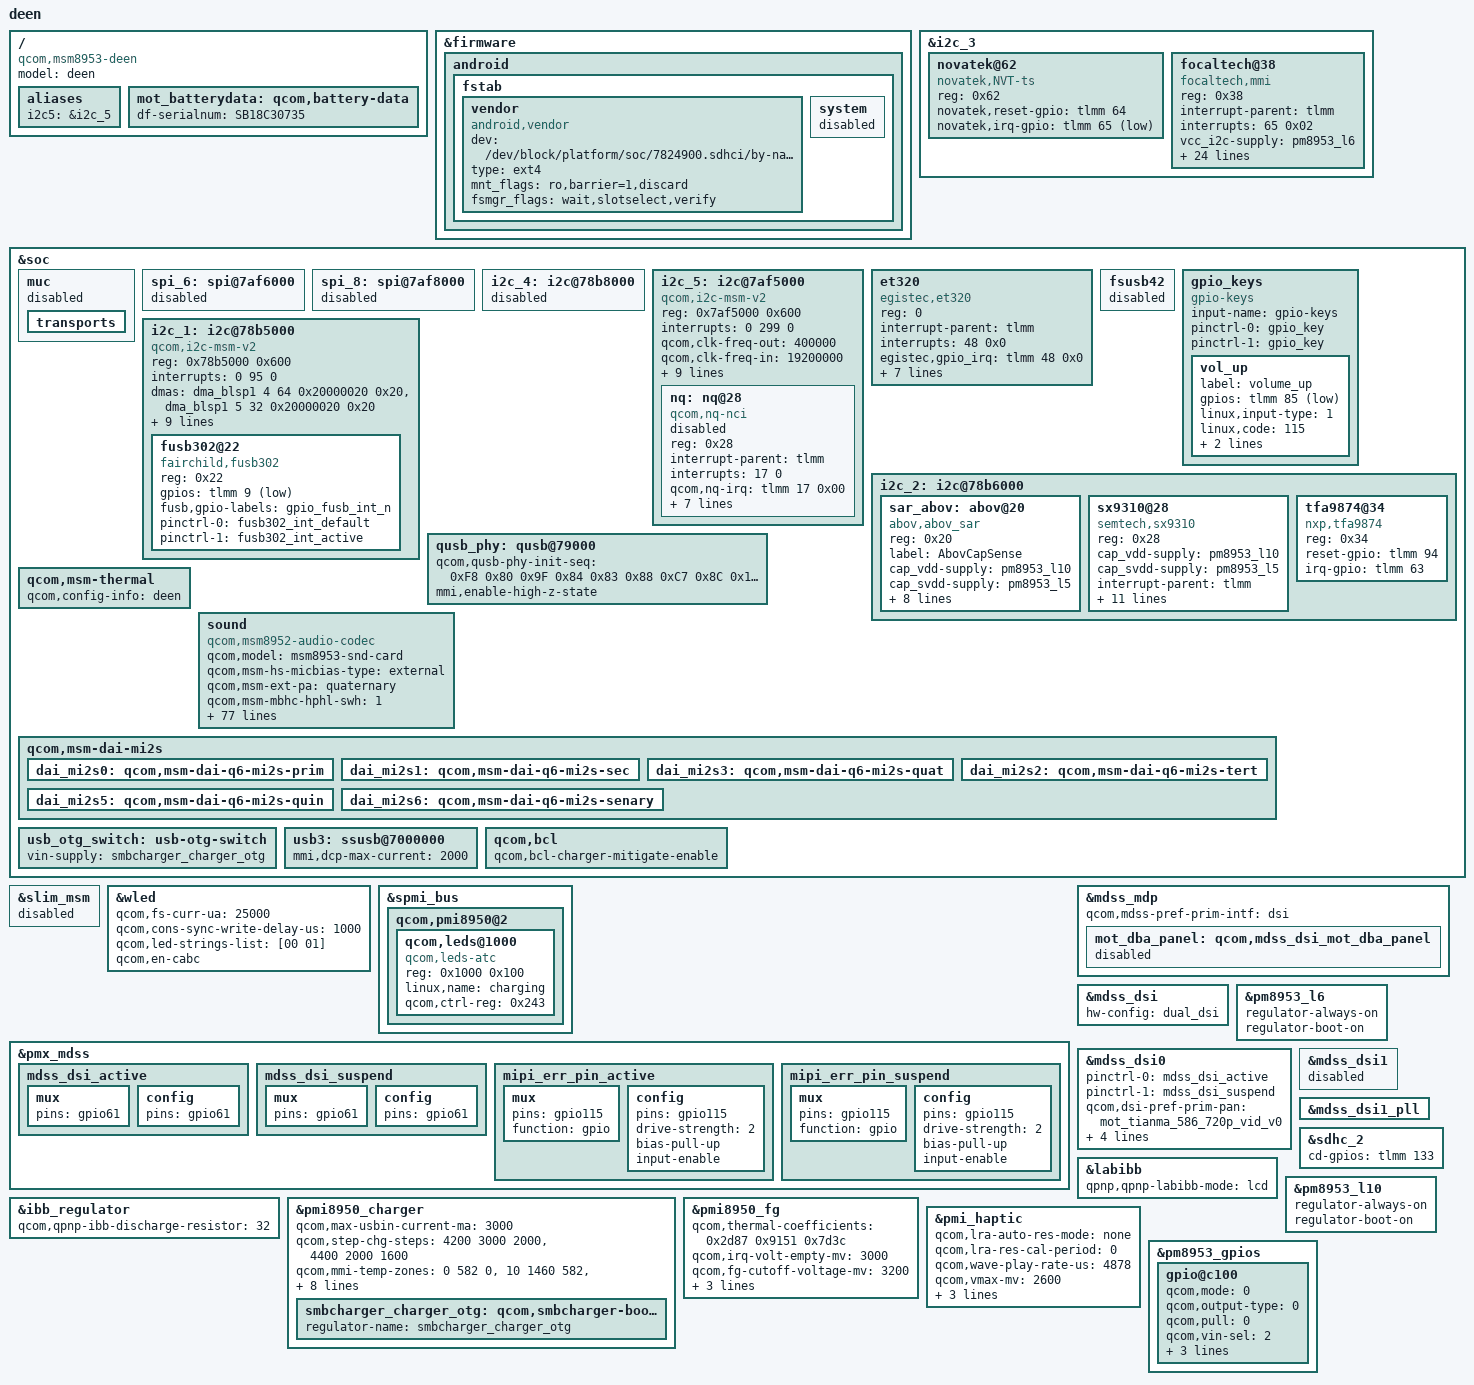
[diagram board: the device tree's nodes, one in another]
/* Copyright (c) 2018, Motorola Mobility Inc. All rights reserved.
 *
 * This program is free software; you can redistribute it and/or modify
 * it under the terms of the GNU General Public License version 2 and
 * only version 2 as published by the Free Software Foundation.
 *
 * This program is distributed in the hope that it will be useful,
 * but WITHOUT ANY WARRANTY; without even the implied warranty of
 * MERCHANTABILITY or FITNESS FOR A PARTICULAR PURPOSE.  See the
 * GNU General Public License for more details.
 */

#include "msm8953-moto-common.dtsi"
#include "dsi-panel-mot-tianma-586-720p-vid.dtsi"
#include "dsi-panel-mot-nova-586-hd-vid.dtsi"
#include "msm8953-deen-pinctrl.dtsi"
#include "msm8953-camera-sensor-mot-deen.dtsi"

 / {
	model = "deen";
	compatible = "qcom,msm8953-deen", "qcom,msm8953-moto",
			"qcom,msm8953";
	aliases {
		i2c5 = &i2c_5;
	};
};

&firmware {
	android {
		fstab {
			vendor {
				compatible = "android,vendor";
				dev = "/dev/block/platform/soc/7824900.sdhci/by-name/vendor";
				type = "ext4";
				mnt_flags = "ro,barrier=1,discard";
				fsmgr_flags = "wait,slotselect,verify";
				status = "ok";
			};
			system {
				status = "disable";
			};
		};
	};
};

&i2c_3 {
	status = "ok";
	/delete-node/ synaptics_dsx_i2c@20;
	novatek@62 {
		compatible = "novatek,NVT-ts";
		reg = <0x62>;
		status = "ok";
		novatek,reset-gpio = <&tlmm 64 0x00>;
		novatek,irq-gpio = <&tlmm 65 0x2001>;
	};

	focaltech@38{
		compatible = "focaltech,mmi";
		reg = <0x38>;
		interrupt-parent = <&tlmm>;
		interrupts = <65 0x02>;
		vcc_i2c-supply = <&pm8953_l6>;
		pinctrl-names = "pmx_ts_active","pmx_ts_suspend","pmx_ts_release";
		pinctrl-0 = <&ts_int_active &ts_reset_active>;
		pinctrl-1 = <&ts_int_suspend &ts_reset_suspend>;
		pinctrl-2 = <&ts_release>;
		focaltech,name = "ft8006u";
		focaltech,family-id = <0xf0>;
		focaltech,reset-gpio = <&tlmm 64 0x01>;
		focaltech,irq-gpio = <&tlmm 65 0x02>;
		focaltech,display-coords = <0 0 720 1520>;
		focaltech,max-touch-number = <10>;
		focaltech,no-force-update;
		focaltech,i2c-pull-up;
		focaltech,group-id = <1>;
		focaltech,hard-reset-delay-ms = <20>;
		focaltech,soft-reset-delay-ms = <200>;
		focaltech,num-max-touches = <10>;
		focaltech,fw-delay-aa-ms = <30>;
		focaltech,fw-delay-55-ms = <30>;
		focaltech,fw-upgrade-id1 = <0x79>;
		focaltech,fw-upgrade-id2 = <0x08>;
		focaltech,fw-delay-readid-ms = <10>;
		focaltech,fw-delay-era-flsh-ms = <2000>;
		focaltech,fw-auto-cal;
		focaltech,resume-in-workqueue;
		focaltech,ignore-id-check;
	};
};

&soc {

	muc: muc {
		status = "disabled";
		transports {
			/delete-node/ i2c@78b5000;
		};
	};
	spi_6: spi@7af6000 { /* BLSP2 QUP2 */
		status = "disabled";
	};
	spi_8: spi@7af8000 { /* BLSP2 QUP3 */
		status = "disabled";
		/delete-node/ fpc_fpc1020@0;
	};

	i2c_4: i2c@78b8000 {
		status = "disabled";
		/delete-node/ motosh@43;
	};

	i2c_5: i2c@7af5000 { /* BLSP2 QUP1 */
		status = "okay";
		compatible = "qcom,i2c-msm-v2";
		#address-cells = <1>;
		#size-cells = <0>;
		reg-names = "qup_phys_addr";
		reg = <0x7af5000 0x600>;
		interrupt-names = "qup_irq";
		interrupts = <0 299 0>;
		qcom,clk-freq-out = <400000>;
		qcom,clk-freq-in  = <19200000>;
		clock-names = "iface_clk", "core_clk";
		clocks = <&clock_gcc clk_gcc_blsp2_ahb_clk>,
		       <&clock_gcc clk_gcc_blsp2_qup1_i2c_apps_clk>;
		pinctrl-names = "i2c_active", "i2c_sleep";
		pinctrl-0 = <&i2c_5_active>;
		pinctrl-1 = <&i2c_5_sleep>;
		qcom,noise-rjct-scl = <0>;
		qcom,noise-rjct-sda = <0>;
		qcom,master-id = <84>;
		dmas = <&dma_blsp2 4 64 0x20000020 0x20>,
		     <&dma_blsp2 5 32 0x20000020 0x20>;
		dma-names = "tx", "rx";

		nq:nq@28 {              /* NFC PN553 */
			compatible = "qcom,nq-nci";
			status = "/chosen", "mmi,nfc", "true";
			reg = <0x28>;
			interrupt-parent = <&tlmm>;
			interrupts = <17 0>;
			interrupt-names = "nfc_irq";
			qcom,nq-irq = <&tlmm 17 0x00>;
			qcom,nq-ven = <&tlmm 16 0x00>;
			qcom,nq-firm = <&tlmm 62 0x00>;
			qcom,nq-clkreq = <&pm8953_gpios 2 0x00>;
			qcom,clk-src = "BBCLK2";
			clocks = <&clock_gcc clk_bb_clk2_pin>;
			clock-names = "ref_clk";
			pinctrl-names = "default";
			pinctrl-0 = <&nfc_irq_default &nfc_ven_default
					&nfc_firm_default>;
		};
	};

	et320: et320{
		compatible = "egistec,et320";
		status = "ok";
		reg = <0>;
		interrupt-parent = <&tlmm>;
		interrupts = <48 0x0>;
		egistec,gpio_irq    = <&tlmm 48 0x0>;
		egistec,gpio_rst    = <&tlmm 8 0x0>;
		egistec,gpio_ldo1p8_en = <&tlmm 36 0x0>;
		egistec,gpio_ldo3p3_en = <&tlmm 12 0x0>;
		pinctrl-names = "default", "suspend";
		pinctrl-0 =
		<&rst_active &int_active &ldo_en_active &ldo3_en_active>;
		pinctrl-1 =
		<&rst_suspend &int_suspend &ldo_en_suspend &ldo3_en_suspend>;
	};


	fsusb42 {
		status = "disabled";
	};

	gpio_keys {
		compatible = "gpio-keys";
		input-name = "gpio-keys";
		pinctrl-names = "tlmm_gpio_key_active","tlmm_gpio_key_suspend";
		pinctrl-0 = <&gpio_key>;
		pinctrl-1 = <&gpio_key>;

		vol_up {
			label = "volume_up";
			gpios = <&tlmm 85 0x1>;
			linux,input-type = <1>;
			linux,code = <115>;
			gpio-key,wakeup;
			debounce-interval = <15>;
		};
	};

	i2c_1: i2c@78b5000 {
		compatible = "qcom,i2c-msm-v2";
		#address-cells = <1>;
		#size-cells = <0>;
		reg-names = "qup_phys_addr";
		reg = <0x78b5000 0x600>;
		interrupt-names = "qup_irq";
		interrupts = <0 95 0>;
		dmas = <&dma_blsp1 4 64 0x20000020 0x20>,
			<&dma_blsp1 5 32 0x20000020 0x20>;
		dma-names = "tx", "rx";
		qcom,master-id = <86>;
		qcom,clk-freq-out = <400000>;
		qcom,clk-freq-in  = <19200000>;
		pinctrl-names = "i2c_active", "i2c_sleep";
		pinctrl-0 = <&i2c_1_active>;
		pinctrl-1 = <&i2c_1_sleep>;
		qcom,noise-rjct-scl = <0>;
		qcom,noise-rjct-sda = <0>;
		clock-names = "iface_clk", "core_clk";
		clocks = <&clock_gcc clk_gcc_blsp1_ahb_clk>,
			 <&clock_gcc clk_gcc_blsp1_qup1_i2c_apps_clk>;

		fusb302@22 {
			compatible = "fairchild,fusb302";
			reg = <0x22>;
			gpios = <&tlmm 9 1>; /* FUSB302_INT_N, in */
			fusb,gpio-labels = "gpio_fusb_int_n";
			pinctrl-names = "default", "active";
			pinctrl-0 = <&fusb302_int_default>;
			pinctrl-1 = <&fusb302_int_active>;
		};
	};

	i2c_2: i2c@78b6000 { /* BLSP1 QUP2 */
		/delete-node/ cs35l34@40;
		/delete-node/ stmvl53l0@29;
		/delete-node/ fusb302@22;
		/delete-node/ pnxxx@28;
		/delete-node/ usb3813@2D;

		sar_abov:abov@20 {
			compatible = "abov,abov_sar";
			reg = <0x20>;
			label = "AbovCapSense";
			cap_vdd-supply = <&pm8953_l10>;
			cap_svdd-supply = <&pm8953_l5>;
			interrupt-parent = <&tlmm>;
			interrupts = <86 0x2008>;
			gpios = <&tlmm 86 0x2008>; /* IRQ */
			pinctrl-names = "default";
			pinctrl-0 = <&abov_int_default>;
			cap,use_channel_top = <0x01>;
			cap,use_channel_bottom = <0x00>;
			reg_array_len = <0>;
			reg_array_val = <>;
		};

		sx9310@28 {
			compatible = "semtech,sx9310";
			reg = <0x28>;
			cap_vdd-supply = <&pm8953_l10>;
			cap_svdd-supply = <&pm8953_l5>;
			interrupt-parent = <&tlmm>;
			interrupts = <86 0x2008>;
			gpios = <&tlmm 86 0x2008>; /* IRQ */
			pinctrl-names = "default";
			pinctrl-0 = <&sx9310_int_default>;
			cap,use_channel = <0x0f>;
			cap,use_channel_top = <0x02>;
			cap,use_channel_bottom = <0x01>;
			cap,raw_data_channel = <0x01>;
			cap,scan_period = <0x00>;
			reg_array_len = <11>;
			reg_array_val = <0x10 0x0f
					0x12 0x0b
					0x13 0x0F
					0x15 0xc3
					0x17 0x4b
					0x18 0x51
					0x19 0x51
					0x21 0x18
					0x22 0x09
					0x23 0x17
					0x2a 0x01>;
		};

		tfa9874@34 {
			compatible = "nxp,tfa9874";
			reg = <0x34>;
			reset-gpio = <&tlmm 94 0>;
			irq-gpio = <&tlmm 63 0>;
			status = "ok";
		};
	};

	qusb_phy: qusb@79000 {
		qcom,qusb-phy-init-seq = <0xF8 0x80
					0x9F 0x84
					0x83 0x88
					0xC7 0x8C
					0x14 0x9C
					0x30 0x08
					0x79 0x0C
					0x21 0x10
					0x00 0x90
					0x9F 0x1C
					0x00 0x18>;
		/*Make sure QUSB PHY is into proper state to
		  avoid interfering USB charger detection*/
		mmi,enable-high-z-state;
	};

	qcom,msm-thermal {
		qcom,config-info = "deen";
	};
	/delete-node/ hd3ss460;

	sound {
		status = "okay";
		compatible = "qcom,msm8952-audio-codec";
		qcom,model = "msm8953-snd-card";
		qcom,msm-hs-micbias-type = "external";
		qcom,msm-ext-pa = "quaternary";
		qcom,msm-mbhc-hphl-swh = <1>;
		qcom,msm-mbhc-gnd-swh = <1>;
		qcom,msm-micbias2-ext-cap;

		qcom,audio-routing =
			"RX_BIAS", "MCLK",
			"INT_LDO_H", "MCLK",
			"MIC BIAS External", "Handset Mic",
			"MIC BIAS External2", "Headset Mic",
			"MIC BIAS External", "Secondary Mic",
			"AMIC1", "MIC BIAS External",
			"AMIC2", "MIC BIAS External2",
			"AMIC3", "MIC BIAS External";

		/delete-property/ asoc-wsa-codec-names;
		/delete-property/ asoc-wsa-codec-prefixes;
		/delete-property/ msm-vdd-wsa-switch-supply;
		/delete-property/ qcom,msm-vdd-wsa-switch-voltage;
		/delete-property/ qcom,msm-vdd-wsa-switch-current;
		/delete-property/ qcom,hdmi-dba-codec-rx;

		qcom,msm-gpios =
			"pri_i2s",
			"us_eu_gpio",
			"quat_i2s";
		qcom,pinctrl-names =
			"all_off",
			"pri_i2s_act",
			"us_eu_gpio_act",
			"pri_i2s_us_eu_gpio_act",
			"quat_i2s_act",
			"quat_pri_i2s_act",
			"quat_us_eu_gpio_act",
			"quat_pri_i2s_us_eu_gpio_act";
		pinctrl-names =
			"all_off",
			"pri_i2s_act",
			"us_eu_gpio_act",
			"pri_i2s_us_eu_gpio_act",
			"quat_i2s_act",
			"quat_pri_i2s_act",
			"quat_us_eu_gpio_act",
			"quat_pri_i2s_us_eu_gpio_act";

		pinctrl-0 = <&cdc_pdm_lines_sus
				&cdc_pdm_lines_2_sus &cross_conn_det_sus
				&pri_tlmm_lines_sus &pri_tlmm_ws_sus &sec_tlmm_lines_sus>;
		pinctrl-1 = <&cdc_pdm_lines_act
				&cdc_pdm_lines_2_act &cross_conn_det_sus
				&pri_tlmm_lines_sus &pri_tlmm_ws_sus &sec_tlmm_lines_sus>;
		pinctrl-2 = <&cdc_pdm_lines_sus
				&cdc_pdm_lines_2_sus &cross_conn_det_act
				&pri_tlmm_lines_sus &pri_tlmm_ws_sus &sec_tlmm_lines_sus>;
		pinctrl-3 = <&cdc_pdm_lines_act
				&cdc_pdm_lines_2_act &cross_conn_det_act
				&pri_tlmm_lines_sus &pri_tlmm_ws_sus &sec_tlmm_lines_sus>;
		pinctrl-4 = <&cdc_pdm_lines_sus
				&cdc_pdm_lines_2_sus &cross_conn_det_sus
				&sec_tlmm_lines_act>;
		pinctrl-5 = <&cdc_pdm_lines_act
				&cdc_pdm_lines_2_act &cross_conn_det_sus
				&sec_tlmm_lines_act>;
		pinctrl-6 = <&cdc_pdm_lines_sus
				&cdc_pdm_lines_2_sus &cross_conn_det_act
				&sec_tlmm_lines_act>;
		pinctrl-7 = <&cdc_pdm_lines_act
				&cdc_pdm_lines_2_act &cross_conn_det_act
				&sec_tlmm_lines_act>;

		asoc-platform = <&pcm0>, <&pcm1>, <&pcm2>, <&voip>, <&voice>,
			<&loopback>, <&compress>, <&hostless>,
			<&afe>, <&lsm>, <&routing>, <&cpe>, <&lpa>;
		asoc-platform-names = "msm-pcm-dsp.0", "msm-pcm-dsp.1",
			"msm-pcm-dsp.2", "msm-voip-dsp",
			"msm-pcm-voice", "msm-pcm-loopback",
			"msm-compress-dsp", "msm-pcm-hostless",
			"msm-pcm-afe", "msm-lsm-client",
			"msm-pcm-routing", "msm-cpe-lsm",
			"msm-pcm-lpa";

		asoc-cpu = <&dai_pri_auxpcm>,
				<&dai_mi2s0>, <&dai_mi2s1>,
				<&dai_mi2s2>, <&dai_mi2s3>,
				<&dai_mi2s5>, <&dai_mi2s6>,
				<&sb_0_rx>, <&sb_0_tx>, <&sb_1_rx>, <&sb_1_tx>,
				<&sb_3_rx>, <&sb_3_tx>, <&sb_4_rx>, <&sb_4_tx>,
				<&bt_sco_rx>, <&bt_sco_tx>,
				<&int_fm_rx>, <&int_fm_tx>,
				<&afe_pcm_rx>, <&afe_pcm_tx>,
				<&afe_proxy_rx>, <&afe_proxy_tx>,
				<&incall_record_rx>, <&incall_record_tx>,
				<&incall_music_rx>, <&incall_music_2_rx>;
		asoc-cpu-names = "msm-dai-q6-auxpcm.1",
				"msm-dai-q6-mi2s.0", "msm-dai-q6-mi2s.1",
				"msm-dai-q6-mi2s.2", "msm-dai-q6-mi2s.3",
				"msm-dai-q6-mi2s.5", "msm-dai-q6-mi2s.6",
				"msm-dai-q6-dev.16384", "msm-dai-q6-dev.16385",
				"msm-dai-q6-dev.16386", "msm-dai-q6-dev.16387",
				"msm-dai-q6-dev.16390", "msm-dai-q6-dev.16391",
				"msm-dai-q6-dev.16392", "msm-dai-q6-dev.16393",
				"msm-dai-q6-dev.12288", "msm-dai-q6-dev.12289",
				"msm-dai-q6-dev.12292", "msm-dai-q6-dev.12293",
				"msm-dai-q6-dev.224", "msm-dai-q6-dev.225",
				"msm-dai-q6-dev.241", "msm-dai-q6-dev.240",
				"msm-dai-q6-dev.32771", "msm-dai-q6-dev.32772",
				"msm-dai-q6-dev.32773", "msm-dai-q6-dev.32770";
		asoc-codec = <&stub_codec>, <&pm8953_diangu_dig>;
		asoc-codec-names = "msm-stub-codec.1", "cajon_codec";

	};

	qcom,msm-dai-mi2s {
		status = "okay";
		dai_mi2s0: qcom,msm-dai-q6-mi2s-prim {
			status = "okay";
		};

		dai_mi2s1: qcom,msm-dai-q6-mi2s-sec {
			status = "okay";
		};

		dai_mi2s3: qcom,msm-dai-q6-mi2s-quat {
			status = "okay";
			/delete-property/ pinctrl-names;
			/delete-property/ pinctrl-0;
			/delete-property/ pinctrl-1;
		};

		dai_mi2s2: qcom,msm-dai-q6-mi2s-tert {
			status = "okay";
		};

		dai_mi2s5: qcom,msm-dai-q6-mi2s-quin {
			status = "okay";
			/delete-property/ pinctrl-names;
			/delete-property/ pinctrl-0;
			/delete-property/ pinctrl-1;
		};

		dai_mi2s6: qcom,msm-dai-q6-mi2s-senary {
			status = "okay";
		};
	};
};


&slim_msm {
	status = "disabled";
	/delete-node/ tasha_codec;
	/delete-node/ marley-codec;
};

&wled {
	qcom,fs-curr-ua = <25000>;
	qcom,cons-sync-write-delay-us = <1000>;
	qcom,led-strings-list = [00 01];
	qcom,en-cabc;
};

&spmi_bus {
	qcom,pmi8950@2 {
		/delete-node/ qcom,leds@a100;

		qcom,leds@1000 {
			status = "ok";
			reg = <0x1000 0x100>;
			compatible = "qcom,leds-atc";
			linux,name = "charging";
			qcom,ctrl-reg = <0x243>;
		};
	};
};

&pmx_mdss {
	mdss_dsi_active {
		mux {
			pins = "gpio61";
		};

		config {
			pins = "gpio61";
		};
	};

	mdss_dsi_suspend {
		mux {
			pins = "gpio61";
		};

		config {
			pins = "gpio61";
		};
	};

	mipi_err_pin_active: mipi_err_pin_active {
		mux {
			pins = "gpio115";
			function = "gpio";
		};

		config {
			pins = "gpio115";
			drive-strength = <2>; /* 2 mA */
			bias-pull-up; /* pull up */
			input-enable;
		};
	};

	mipi_err_pin_suspend: mipi_err_pin_suspend {
		mux {
			pins = "gpio115";
			function = "gpio";
		};

		config {
			pins = "gpio115";
			drive-strength = <2>; /* 2 mA */
			bias-pull-up; /* pull up */
			input-enable;
		};
	};
};

&mdss_mdp {
	qcom,mdss-pref-prim-intf = "dsi";

	mot_dba_panel: qcom,mdss_dsi_mot_dba_panel{
		#include "dsi-panel-mot-mod-fwvga-video-common.dtsi"
	};
};

&mdss_dsi {
	hw-config = "dual_dsi";
};

&pm8953_l6 {
	regulator-always-on;
	regulator-boot-on;
};

&mdss_dsi0 {
	pinctrl-names = "mdss_default", "mdss_sleep";
	pinctrl-0 = <&mdss_dsi_active>;
	pinctrl-1 = <&mdss_dsi_suspend>;

	qcom,dsi-pref-prim-pan = <&mot_tianma_586_720p_vid_v0>;

	/delete-property/ vdd-supply;
	vddio_disp-supply = <&pm8953_l6>;
	vsp_disp-supply = <&lab_regulator>;
	vsn_disp-supply = <&ibb_regulator>;

	qcom,platform-reset-gpio = <&tlmm 61 0>;
};

&mdss_dsi1 {
	status = "disabled";
};

&mdss_dsi1_pll {
	/delete-property/ qcom,dsi-pll-ssc-en;
	/delete-property/ qcom,dsi-pll-ssc-mode;
};

&mot_dba_panel {
	status = "disabled";
};


/* display boost and inverting boost regulators */
&labibb {
	status = "ok";
	qpnp,qpnp-labibb-mode = "lcd";
};

&ibb_regulator {
	qcom,qpnp-ibb-discharge-resistor = <32>;
};

&sdhc_2 {
	cd-gpios = <&tlmm 133 0x0>;
};

&soc {
	usb_otg_switch: usb-otg-switch {
		vin-supply = <&smbcharger_charger_otg>;
		/delete-property/ gpio;
	};

	usb3: ssusb@7000000{
		/delete-property/ pinctrl-names;
		/delete-property/ pinctrl-0;
		/delete-property/ qcom,otg-fault-gpio;
		mmi,dcp-max-current = <2000>;
	};

	qcom,bcl {
		qcom,bcl-charger-mitigate-enable;
	};
};

&pmi8950_charger {
	/delete-property/ pinctrl-names;
	/delete-property/ pinctrl-0;
	/delete-property/ gpios;
	/delete-property/ gpio-names;

	qcom,max-usbin-current-ma = <3000>;
	qcom,step-chg-steps = <4200 3000 2000>,
				<4400 2000 1600>;
	qcom,mmi-temp-zones = <0 582 0>,
				<10 1460 582>,
				<15 1460 1460>,
				<45 3000 2000>,
				<60 1460 0>;
	qcom,auto-voltage-comp-mv = <150>;
	qcom,prop-flash-active;
	qcom,enable-charging-limit;
	qcom,upper-limit-capacity = <75>;
	qcom,lower-limit-capacity = <60>;
	qcom,pd-charger-force-5v;
	qcom,stepchg-iterm-ma = <146>;

	smbcharger_charger_otg: qcom,smbcharger-boost-otg {
		status = "okay";
		regulator-name = "smbcharger_charger_otg";
	};
};

/{
	/delete-node/ qcom,battery-data;
	mot_batterydata: qcom,battery-data {
		df-serialnum = "SB18C30735";
		#include "batterydata-je40-scud.dtsi"
		#include "batterydata-je40-atl.dtsi"
	};
};

&pmi8950_fg {
	/delete-property/ qcom,battery-data;
	qcom,thermal-coefficients =  /bits/ 16 <0x2d87 0x9151 0x7d3c>;
	qcom,irq-volt-empty-mv = <3000>;
	qcom,fg-cutoff-voltage-mv = <3200>;
	qcom,battery-data = <&mot_batterydata>;
	qcom,cl-vbat-est-thr-uv = <300000>;
	qcom,fg-force-restart-enable;
};

&pmi_haptic {
	qcom,lra-auto-res-mode="none";
	qcom,lra-res-cal-period = <0>;
	qcom,wave-play-rate-us = <4878>;
	qcom,vmax-mv = <2600>;
	qcom,vmax-low-mv = <2600>;
	qcom,ilim-ma = <100>;
	qcom,brake-pattern = [03 03 00 00];
};

&pm8953_l10 {
	regulator-always-on;
	regulator-boot-on;
};

&pm8953_gpios {
	/* GPIO 2 (NFC_CLK_REQ) */
	gpio@c100 {
		qcom,mode = <0>;
		qcom,output-type = <0>;
		qcom,pull = <0>;
		qcom,vin-sel = <2>;
		qcom,out-strength = <3>;
		qcom,src-sel = <0>;
		qcom,master-en = <1>;
		status = "okay";
	};
};
